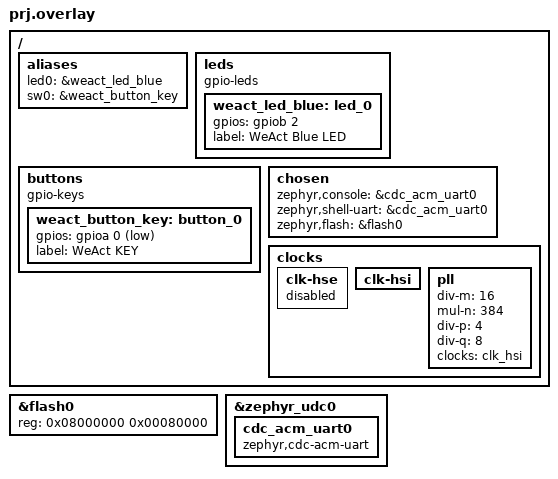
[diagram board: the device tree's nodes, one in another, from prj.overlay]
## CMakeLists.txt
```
cmake_minimum_required(VERSION 3.20.0)

# If a project devicetree overlay exists, pass it to the Zephyr build
# so the overlay is applied during the initial configure step.
if(EXISTS "${CMAKE_CURRENT_SOURCE_DIR}/prj.overlay")
	set(DTC_OVERLAY_FILE "${CMAKE_CURRENT_SOURCE_DIR}/prj.overlay" CACHE STRING "Device tree overlay file for project")
endif()

find_package(Zephyr REQUIRED HINTS $ENV{ZEPHYR_BASE})

project(stm32f412_template)

target_sources(app PRIVATE src/main.c)
```

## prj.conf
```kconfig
# WeAct STM32F412 template (Zephyr)
# Hardware: STM32F412RET6, 512 KiB flash, 256 KiB SRAM

CONFIG_FLASH_SIZE=512
CONFIG_SRAM_SIZE=256

CONFIG_GPIO=y
CONFIG_SERIAL=y
CONFIG_PRINTK=y
CONFIG_CONSOLE=y
CONFIG_STDOUT_CONSOLE=y
CONFIG_UART_CONSOLE=y
CONFIG_UART_LINE_CTRL=y

CONFIG_USB_DEVICE_STACK=y
CONFIG_USB_CDC_ACM=y
CONFIG_USB_DEVICE_VID=0x0483
CONFIG_USB_DEVICE_PID=0xDF11

CONFIG_LOG=y
CONFIG_LOG_DEFAULT_LEVEL=3

# Keep the app tiny and deterministic for first bring-up.
CONFIG_MAIN_STACK_SIZE=1024
```

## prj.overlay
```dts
#include <zephyr/dt-bindings/gpio/gpio.h>

/ {
	aliases {
		led0 = &weact_led_blue;
		sw0 = &weact_button_key;
	};

	leds {
		compatible = "gpio-leds";
		weact_led_blue: led_0 {
			/* WeAct STM32F4 64-pin CoreBoard: blue LED on PB2 */
			gpios = <&gpiob 2 GPIO_ACTIVE_HIGH>;
			label = "WeAct Blue LED";
		};
	};

	buttons {
		compatible = "gpio-keys";
		weact_button_key: button_0 {
			/* WeAct STM32F4 64-pin CoreBoard: KEY button on PA0 */
			gpios = <&gpioa 0 (GPIO_PULL_UP | GPIO_ACTIVE_LOW)>;
			label = "WeAct KEY";
		};
	};

	chosen {
		zephyr,console = &cdc_acm_uart0;
		zephyr,shell-uart = &cdc_acm_uart0;
		zephyr,flash = &flash0;
	};
};

/* STM32F412RET6 provides 512 KiB internal flash. */
&flash0 {
	reg = <0x08000000 0x00080000>;
};

&zephyr_udc0 {
	status = "okay";

	cdc_acm_uart0: cdc_acm_uart0 {
		compatible = "zephyr,cdc-acm-uart";
		status = "okay";
	};
};

/*
 * Nucleo-F412ZG board config expects HSE bypass from ST-LINK MCO.
 * WeAct boards do not provide that clock, so boot hangs waiting for HSE.
 * Force RCC to use HSI as PLL source.
 */
/ {
	clocks {
		clk-hse {
			status = "disabled";
		};

		clk-hsi {
			status = "okay";
		};

		pll {
			/* 16 MHz HSI -> 96 MHz SYSCLK, 48 MHz USB clock via PLLQ */
			div-m = <16>;
			mul-n = <384>;
			div-p = <4>;
			div-q = <8>;
			clocks = <&clk_hsi>;
			status = "okay";
		};
	};
};
```

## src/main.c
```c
#include <zephyr/kernel.h>
#include <zephyr/drivers/gpio.h>
#include <zephyr/usb/usb_device.h>
#include <zephyr/logging/log.h>

LOG_MODULE_REGISTER(app, LOG_LEVEL_INF);

#define LED0_NODE DT_ALIAS(led0)

#if !DT_NODE_HAS_STATUS(LED0_NODE, okay)
#error "DT alias led0 is not defined in the board overlay"
#endif

static const struct gpio_dt_spec led = GPIO_DT_SPEC_GET(LED0_NODE, gpios);

int main(void)
{
    int ret;
    uint32_t blink_count = 0;

    /* Enable USB device stack so console/logging goes over CDC ACM */
    ret = usb_enable(NULL);
    if (ret) {
        LOG_ERR("usb_enable failed: %d", ret);
    } else {
        LOG_INF("usb_enable returned 0 (OK)");
    }

    if (!gpio_is_ready_dt(&led))
    {
        LOG_ERR("LED GPIO device is not ready");
        return -ENODEV;
    }

    ret = gpio_pin_configure_dt(&led, GPIO_OUTPUT_INACTIVE);
    if (ret != 0)
    {
        LOG_ERR("Failed to configure LED GPIO (err %d)", ret);
        return ret;
    }

    LOG_INF("WeAct STM32F412 app started");

    while (1)
    {
        ret = gpio_pin_toggle_dt(&led);
        if (ret != 0)
        {
            LOG_ERR("Failed to toggle LED (err %d)", ret);
        }

        LOG_INF("blink %u", blink_count++);
        k_msleep(500);
    }
}
```
